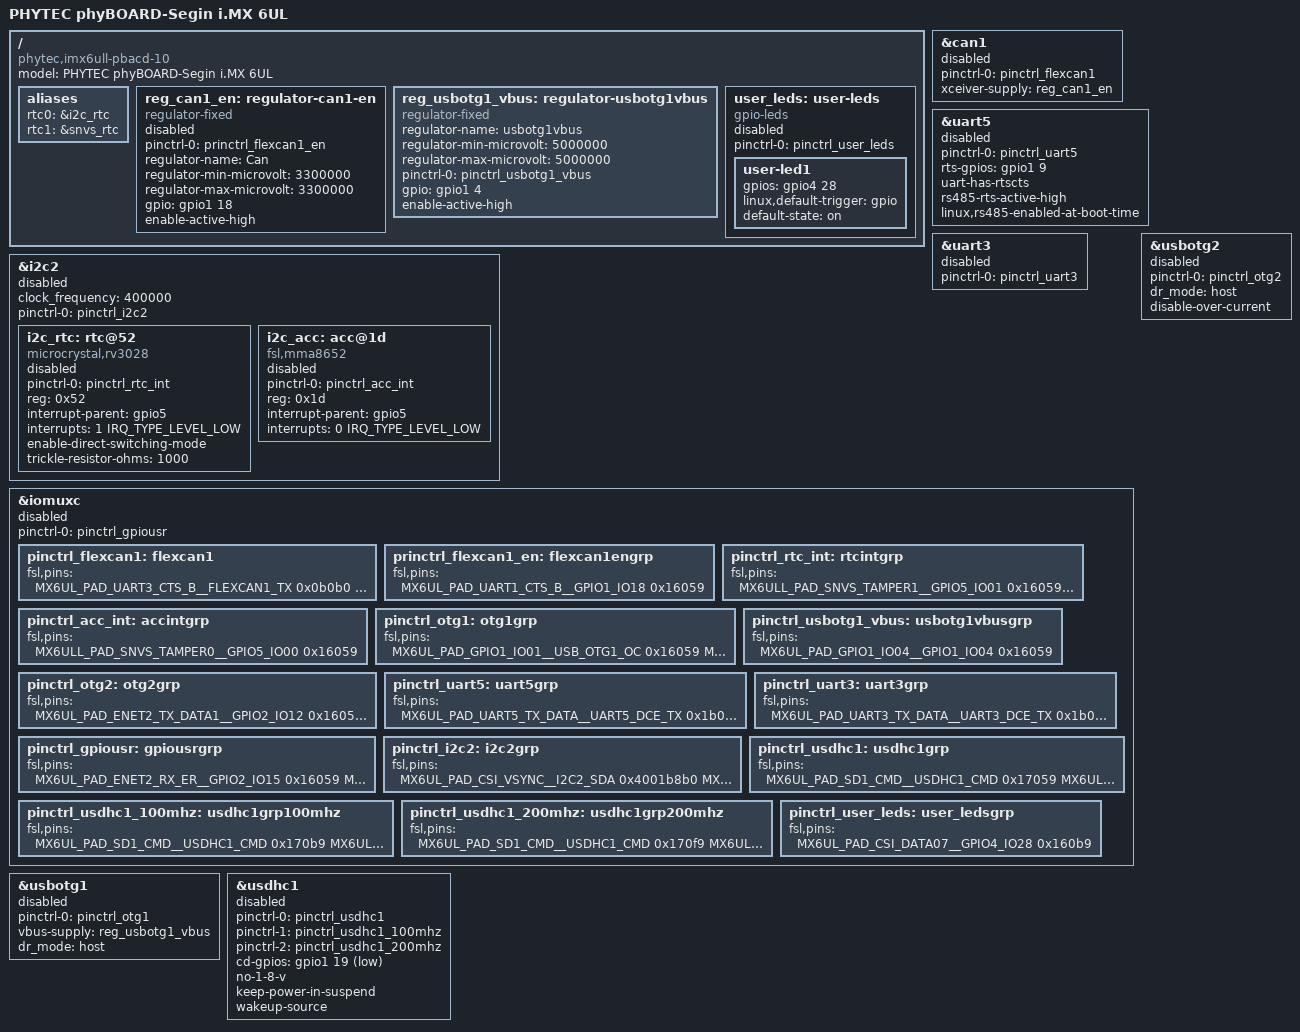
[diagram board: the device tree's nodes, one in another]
// SPDX-License-Identifier: (GPL-2.0+ OR MIT)
/*
 * Copyright (C) 2020 PHYTEC Messtechnik GmbH
 * Author: Felix Siebel <f.siebel@phytec.de>
 */
 
 #include <dt-bindings/input/input.h>
 
/ {

	model = "PHYTEC phyBOARD-Segin i.MX 6UL";
	compatible = "phytec,imx6ull-pbacd-10", "phytec,imx6ull-pcl063","fsl,imx6ull";

	aliases {
		rtc0 = &i2c_rtc;
		rtc1 = &snvs_rtc;
	};

	reg_can1_en: regulator-can1-en {
		compatible = "regulator-fixed";
		pinctrl-names = "default";
		pinctrl-0 = <&princtrl_flexcan1_en>;
		regulator-name = "Can";
		regulator-min-microvolt = <3300000>;
		regulator-max-microvolt = <3300000>;
		gpio = <&gpio1 18 GPIO_ACTIVE_HIGH>;
		enable-active-high;
		status = "disabled";
	};
	
	reg_usbotg1_vbus: regulator-usbotg1vbus {
		compatible = "regulator-fixed";
		regulator-name = "usbotg1vbus";
		regulator-min-microvolt = <5000000>;
		regulator-max-microvolt = <5000000>;
		pinctrl-names = "default";
		pinctrl-0 = <&pinctrl_usbotg1_vbus>;
		gpio = <&gpio1 4 GPIO_ACTIVE_HIGH>;
		enable-active-high;
	};

	user_leds: user-leds {
		compatible = "gpio-leds";
		pinctrl-names = "default";
		pinctrl-0 = <&pinctrl_user_leds>;
		status = "disabled";

		user-led1 {
			gpios = <&gpio4 28 GPIO_ACTIVE_HIGH>;
			linux,default-trigger = "gpio";
			default-state = "on";
		};
	};
};


&can1 {
	pinctrl-names = "default";
	pinctrl-0 = <&pinctrl_flexcan1>;
	xceiver-supply = <&reg_can1_en>;
	status = "disabled";
};

&i2c2 {	
	clock_frequency = <400000>;
	pinctrl-names = "default";
	pinctrl-0 = <&pinctrl_i2c2>;
	status = "disabled";
	
	i2c_rtc: rtc@52 {
		pinctrl-names = "default";
		pinctrl-0 = <&pinctrl_rtc_int>;
		compatible = "microcrystal,rv3028";
		reg = <0x52>;
		interrupt-parent = <&gpio5>;
		interrupts = <1 IRQ_TYPE_LEVEL_LOW>;
		enable-direct-switching-mode;
        trickle-resistor-ohms = <1000>;
		status = "disabled";       
	};
	i2c_acc: acc@1d {
		pinctrl-names = "default";
		pinctrl-0 = <&pinctrl_acc_int>;
		compatible = "fsl,mma8652";
		reg = <0x1d>;
		interrupt-parent = <&gpio5>;
		interrupts = <0 IRQ_TYPE_LEVEL_LOW>;
		status = "disabled";
	};
};

&uart5 {
	pinctrl-names = "default";
	pinctrl-0 = <&pinctrl_uart5>;
	rts-gpios = <&gpio1 9 GPIO_ACTIVE_HIGH>;
	uart-has-rtscts;
	rs485-rts-active-high;
    linux,rs485-enabled-at-boot-time;
	status = "disabled";
};

&uart3 {
	pinctrl-names = "default";
	pinctrl-0 = <&pinctrl_uart3>;
	status = "disabled";
};

&iomuxc {
    pinctrl-names = "default";
    pinctrl-0 = <&pinctrl_gpiousr>;
	status = "disabled";
};

&usbotg1 {
	pinctrl-names = "default";
	pinctrl-0 = <&pinctrl_otg1>;
	vbus-supply = <&reg_usbotg1_vbus>;
	dr_mode = "host";
	status = "disabled";
};

&usbotg2 {
	pinctrl-names = "default";
	pinctrl-0 = <&pinctrl_otg2>;
	dr_mode = "host";
	disable-over-current;
	status = "disabled";
};

&usdhc1 {
	pinctrl-names = "default", "state_100mhz", "state_200mhz";
	pinctrl-0 = <&pinctrl_usdhc1>;
	pinctrl-1 = <&pinctrl_usdhc1_100mhz>;
	pinctrl-2 = <&pinctrl_usdhc1_200mhz>;
	cd-gpios = <&gpio1 19 GPIO_ACTIVE_LOW>;
	no-1-8-v;
	keep-power-in-suspend;
	wakeup-source;
	status = "disabled";
};

&iomuxc {
	
	pinctrl_flexcan1: flexcan1 {
		fsl,pins = <
			MX6UL_PAD_UART3_CTS_B__FLEXCAN1_TX	0x0b0b0
			MX6UL_PAD_UART3_RTS_B__FLEXCAN1_RX	0x0b0b0
		>;
	};

	princtrl_flexcan1_en: flexcan1engrp {
		fsl,pins = <
			MX6UL_PAD_UART1_CTS_B__GPIO1_IO18	0x16059
		>;
	};

	pinctrl_rtc_int: rtcintgrp {
		fsl,pins = <
			MX6ULL_PAD_SNVS_TAMPER1__GPIO5_IO01	0x16059
			MX6ULL_PAD_SNVS_TAMPER9__GPIO5_IO09	0x16059
		>;
	};
	pinctrl_acc_int: accintgrp {
		fsl,pins = <
			MX6ULL_PAD_SNVS_TAMPER0__GPIO5_IO00	0x16059
		>;
	};
	
	pinctrl_otg1: otg1grp {
		fsl,pins = <
		MX6UL_PAD_GPIO1_IO01__USB_OTG1_OC		0x16059
		MX6UL_PAD_GPIO1_IO00__ANATOP_OTG1_ID	0x1b0b0
		>;
	};
	
	pinctrl_usbotg1_vbus: usbotg1vbusgrp {
		fsl,pins = <
			MX6UL_PAD_GPIO1_IO04__GPIO1_IO04	0x16059
		>;
	};
	
	pinctrl_otg2: otg2grp {
		fsl,pins = <
		MX6UL_PAD_ENET2_TX_DATA1__GPIO2_IO12	0x16059
		MX6UL_PAD_ENET2_TX_EN__GPIO2_IO13		0x16059
		MX6UL_PAD_GPIO1_IO05__ANATOP_OTG2_ID	0x1b0b0
		>;
	};

	pinctrl_uart5: uart5grp {
		fsl,pins = <
			MX6UL_PAD_UART5_TX_DATA__UART5_DCE_TX	0x1b0b1
			MX6ULL_PAD_UART5_RX_DATA__UART5_DCE_RX	0x1b0b1
			MX6UL_PAD_GPIO1_IO09__GPIO1_IO09		0x1a0b1
		>;
	};
	
	pinctrl_uart3: uart3grp {
		fsl,pins = <
			MX6UL_PAD_UART3_TX_DATA__UART3_DCE_TX	0x1b0b1
			MX6UL_PAD_UART3_RX_DATA__UART3_DCE_RX	0x1b0b1
		>;
	};
	
	pinctrl_gpiousr: gpiousrgrp {
		fsl,pins = <
			MX6UL_PAD_ENET2_RX_ER__GPIO2_IO15		0x16059
			MX6UL_PAD_ENET2_RX_EN__GPIO2_IO10		0x16059
			MX6ULL_PAD_SNVS_TAMPER2__GPIO5_IO02 	0x16059
			MX6ULL_PAD_SNVS_TAMPER3__GPIO5_IO03 	0x16059
		>;
	};
	
	pinctrl_i2c2: i2c2grp {
		fsl,pins = <
			MX6UL_PAD_CSI_VSYNC__I2C2_SDA	0x4001b8b0
			MX6UL_PAD_CSI_HSYNC__I2C2_SCL	0x4001b8b0
		>;
	};

	pinctrl_usdhc1: usdhc1grp {
		fsl,pins = <
			MX6UL_PAD_SD1_CMD__USDHC1_CMD		0x17059
			MX6UL_PAD_SD1_CLK__USDHC1_CLK		0x10059
			MX6UL_PAD_SD1_DATA0__USDHC1_DATA0	0x17059
			MX6UL_PAD_SD1_DATA1__USDHC1_DATA1	0x17059
			MX6UL_PAD_SD1_DATA2__USDHC1_DATA2	0x17059
			MX6UL_PAD_SD1_DATA3__USDHC1_DATA3	0x17059
			MX6UL_PAD_UART1_RTS_B__GPIO1_IO19	0x17059
		>;
	};

	pinctrl_usdhc1_100mhz: usdhc1grp100mhz {
		fsl,pins = <
			MX6UL_PAD_SD1_CMD__USDHC1_CMD		0x170b9
			MX6UL_PAD_SD1_CLK__USDHC1_CLK		0x100b9
			MX6UL_PAD_SD1_DATA0__USDHC1_DATA0	0x170b9
			MX6UL_PAD_SD1_DATA1__USDHC1_DATA1	0x170b9
			MX6UL_PAD_SD1_DATA2__USDHC1_DATA2	0x170b9
			MX6UL_PAD_SD1_DATA3__USDHC1_DATA3	0x170b9
		>;
	};

	pinctrl_usdhc1_200mhz: usdhc1grp200mhz {
		fsl,pins = <
			MX6UL_PAD_SD1_CMD__USDHC1_CMD		0x170f9
			MX6UL_PAD_SD1_CLK__USDHC1_CLK		0x100f9
			MX6UL_PAD_SD1_DATA0__USDHC1_DATA0	0x170f9
			MX6UL_PAD_SD1_DATA1__USDHC1_DATA1	0x170f9
			MX6UL_PAD_SD1_DATA2__USDHC1_DATA2	0x170f9
			MX6UL_PAD_SD1_DATA3__USDHC1_DATA3	0x170f9
		>;
	};

	pinctrl_user_leds: user_ledsgrp {
		fsl,pins = <
			MX6UL_PAD_CSI_DATA07__GPIO4_IO28		0x160b9
		>;
	};
};
